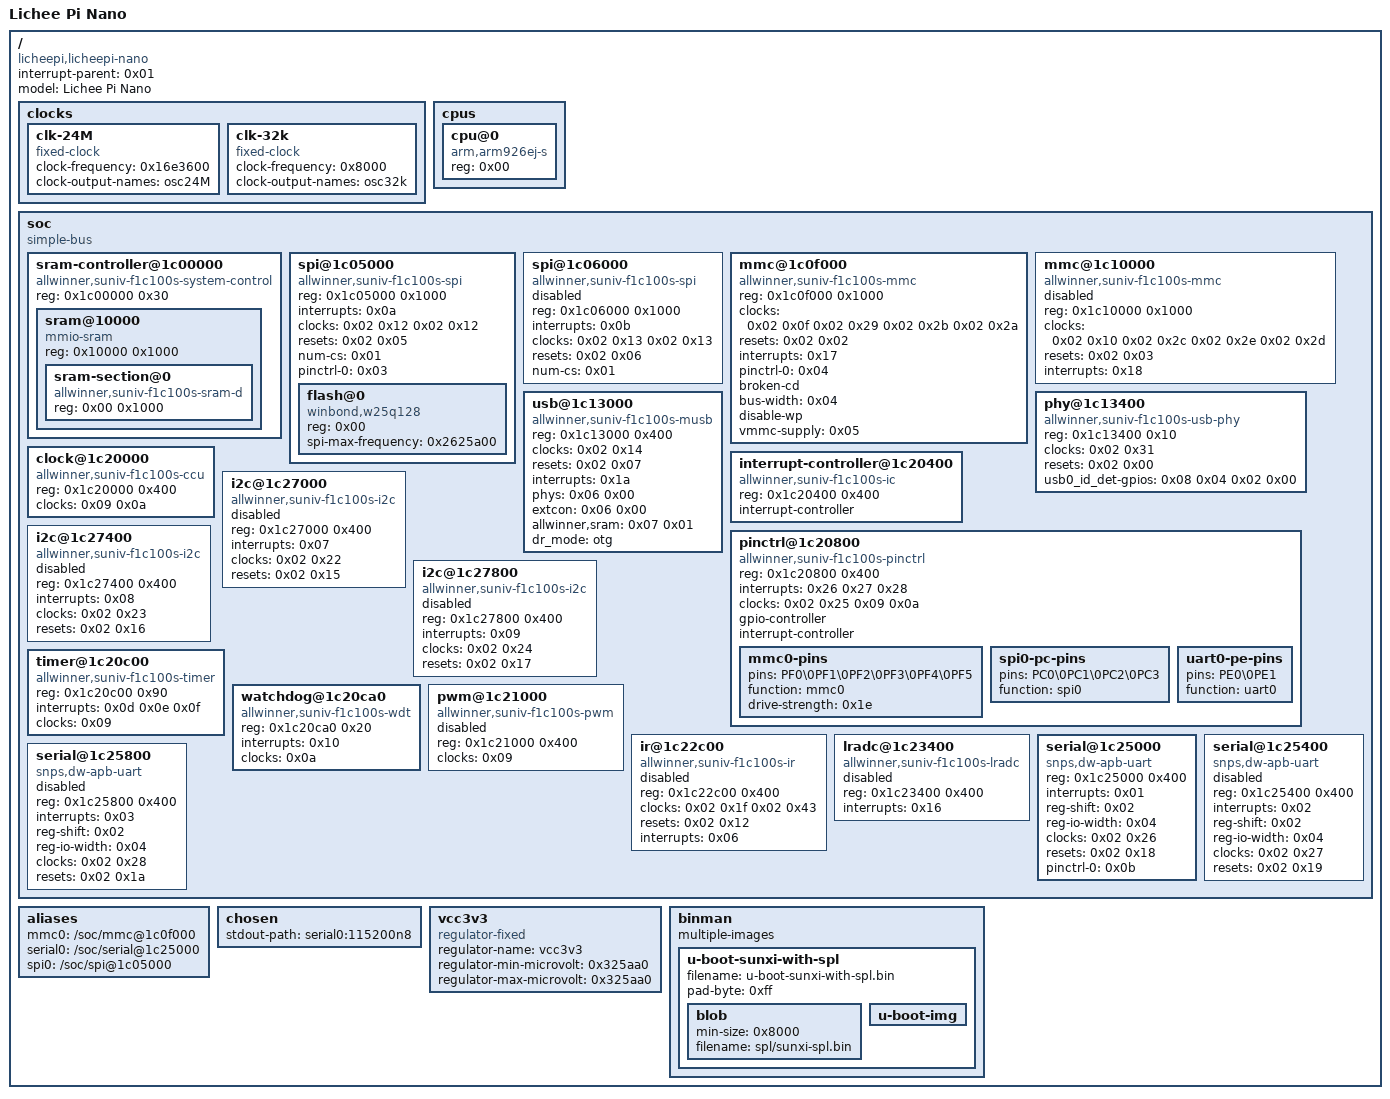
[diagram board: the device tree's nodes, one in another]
/dts-v1/;

/ {
	#address-cells = <0x01>;
	#size-cells = <0x01>;
	interrupt-parent = <0x01>;
	model = "Lichee Pi Nano";
	compatible = "licheepi,licheepi-nano\0allwinner,suniv-f1c100s";

	clocks {

		clk-24M {
			#clock-cells = <0x00>;
			compatible = "fixed-clock";
			clock-frequency = <0x16e3600>;
			clock-output-names = "osc24M";
			phandle = <0x09>;
		};

		clk-32k {
			#clock-cells = <0x00>;
			compatible = "fixed-clock";
			clock-frequency = <0x8000>;
			clock-output-names = "osc32k";
			phandle = <0x0a>;
		};
	};

	cpus {
		#address-cells = <0x01>;
		#size-cells = <0x00>;

		cpu@0 {
			compatible = "arm,arm926ej-s";
			device_type = "cpu";
			reg = <0x00>;
		};
	};

	soc {
		compatible = "simple-bus";
		#address-cells = <0x01>;
		#size-cells = <0x01>;
		ranges;

		sram-controller@1c00000 {
			compatible = "allwinner,suniv-f1c100s-system-control\0allwinner,sun4i-a10-system-control";
			reg = <0x1c00000 0x30>;
			#address-cells = <0x01>;
			#size-cells = <0x01>;
			ranges;

			sram@10000 {
				compatible = "mmio-sram";
				reg = <0x10000 0x1000>;
				#address-cells = <0x01>;
				#size-cells = <0x01>;
				ranges = <0x00 0x10000 0x1000>;
				phandle = <0x0c>;

				sram-section@0 {
					compatible = "allwinner,suniv-f1c100s-sram-d\0allwinner,sun4i-a10-sram-d";
					reg = <0x00 0x1000>;
					status = "okay";
					phandle = <0x07>;
				};
			};
		};

		spi@1c05000 {
			compatible = "allwinner,suniv-f1c100s-spi\0allwinner,sun8i-h3-spi";
			reg = <0x1c05000 0x1000>;
			interrupts = <0x0a>;
			clocks = <0x02 0x12 0x02 0x12>;
			clock-names = "ahb\0mod";
			resets = <0x02 0x05>;
			status = "okay";
			num-cs = <0x01>;
			#address-cells = <0x01>;
			#size-cells = <0x00>;
			pinctrl-names = "default";
			pinctrl-0 = <0x03>;
			phandle = <0x0d>;

			flash@0 {
				#address-cells = <0x01>;
				#size-cells = <0x01>;
				compatible = "winbond,w25q128\0jedec,spi-nor";
				reg = <0x00>;
				spi-max-frequency = <0x2625a00>;
			};
		};

		spi@1c06000 {
			compatible = "allwinner,suniv-f1c100s-spi\0allwinner,sun8i-h3-spi";
			reg = <0x1c06000 0x1000>;
			interrupts = <0x0b>;
			clocks = <0x02 0x13 0x02 0x13>;
			clock-names = "ahb\0mod";
			resets = <0x02 0x06>;
			status = "disabled";
			num-cs = <0x01>;
			#address-cells = <0x01>;
			#size-cells = <0x00>;
			phandle = <0x0e>;
		};

		mmc@1c0f000 {
			compatible = "allwinner,suniv-f1c100s-mmc\0allwinner,sun7i-a20-mmc";
			reg = <0x1c0f000 0x1000>;
			clocks = <0x02 0x0f 0x02 0x29 0x02 0x2b 0x02 0x2a>;
			clock-names = "ahb\0mmc\0output\0sample";
			resets = <0x02 0x02>;
			reset-names = "ahb";
			interrupts = <0x17>;
			pinctrl-names = "default";
			pinctrl-0 = <0x04>;
			status = "okay";
			#address-cells = <0x01>;
			#size-cells = <0x00>;
			broken-cd;
			bus-width = <0x04>;
			disable-wp;
			vmmc-supply = <0x05>;
			phandle = <0x0f>;
		};

		mmc@1c10000 {
			compatible = "allwinner,suniv-f1c100s-mmc\0allwinner,sun7i-a20-mmc";
			reg = <0x1c10000 0x1000>;
			clocks = <0x02 0x10 0x02 0x2c 0x02 0x2e 0x02 0x2d>;
			clock-names = "ahb\0mmc\0output\0sample";
			resets = <0x02 0x03>;
			reset-names = "ahb";
			interrupts = <0x18>;
			status = "disabled";
			#address-cells = <0x01>;
			#size-cells = <0x00>;
			phandle = <0x10>;
		};

		usb@1c13000 {
			compatible = "allwinner,suniv-f1c100s-musb";
			reg = <0x1c13000 0x400>;
			clocks = <0x02 0x14>;
			resets = <0x02 0x07>;
			interrupts = <0x1a>;
			interrupt-names = "mc";
			phys = <0x06 0x00>;
			phy-names = "usb";
			extcon = <0x06 0x00>;
			allwinner,sram = <0x07 0x01>;
			status = "okay";
			dr_mode = "otg";
			phandle = <0x11>;
		};

		phy@1c13400 {
			compatible = "allwinner,suniv-f1c100s-usb-phy";
			reg = <0x1c13400 0x10>;
			reg-names = "phy_ctrl";
			clocks = <0x02 0x31>;
			clock-names = "usb0_phy";
			resets = <0x02 0x00>;
			reset-names = "usb0_reset";
			#phy-cells = <0x01>;
			status = "okay";
			usb0_id_det-gpios = <0x08 0x04 0x02 0x00>;
			phandle = <0x06>;
		};

		clock@1c20000 {
			compatible = "allwinner,suniv-f1c100s-ccu";
			reg = <0x1c20000 0x400>;
			clocks = <0x09 0x0a>;
			clock-names = "hosc\0losc";
			#clock-cells = <0x01>;
			#reset-cells = <0x01>;
			phandle = <0x02>;
		};

		interrupt-controller@1c20400 {
			compatible = "allwinner,suniv-f1c100s-ic";
			reg = <0x1c20400 0x400>;
			interrupt-controller;
			#interrupt-cells = <0x01>;
			phandle = <0x01>;
		};

		pinctrl@1c20800 {
			compatible = "allwinner,suniv-f1c100s-pinctrl";
			reg = <0x1c20800 0x400>;
			interrupts = <0x26 0x27 0x28>;
			clocks = <0x02 0x25 0x09 0x0a>;
			clock-names = "apb\0hosc\0losc";
			gpio-controller;
			interrupt-controller;
			#interrupt-cells = <0x03>;
			#gpio-cells = <0x03>;
			phandle = <0x08>;

			mmc0-pins {
				pins = "PF0\0PF1\0PF2\0PF3\0PF4\0PF5";
				function = "mmc0";
				drive-strength = <0x1e>;
				phandle = <0x04>;
			};

			spi0-pc-pins {
				pins = "PC0\0PC1\0PC2\0PC3";
				function = "spi0";
				phandle = <0x03>;
			};

			uart0-pe-pins {
				pins = "PE0\0PE1";
				function = "uart0";
				phandle = <0x0b>;
			};
		};

		i2c@1c27000 {
			compatible = "allwinner,suniv-f1c100s-i2c\0allwinner,sun6i-a31-i2c";
			reg = <0x1c27000 0x400>;
			interrupts = <0x07>;
			clocks = <0x02 0x22>;
			resets = <0x02 0x15>;
			#address-cells = <0x01>;
			#size-cells = <0x00>;
			status = "disabled";
			phandle = <0x12>;
		};

		i2c@1c27400 {
			compatible = "allwinner,suniv-f1c100s-i2c\0allwinner,sun6i-a31-i2c";
			reg = <0x1c27400 0x400>;
			interrupts = <0x08>;
			clocks = <0x02 0x23>;
			resets = <0x02 0x16>;
			#address-cells = <0x01>;
			#size-cells = <0x00>;
			status = "disabled";
			phandle = <0x13>;
		};

		i2c@1c27800 {
			compatible = "allwinner,suniv-f1c100s-i2c\0allwinner,sun6i-a31-i2c";
			reg = <0x1c27800 0x400>;
			interrupts = <0x09>;
			clocks = <0x02 0x24>;
			resets = <0x02 0x17>;
			#address-cells = <0x01>;
			#size-cells = <0x00>;
			status = "disabled";
			phandle = <0x14>;
		};

		timer@1c20c00 {
			compatible = "allwinner,suniv-f1c100s-timer";
			reg = <0x1c20c00 0x90>;
			interrupts = <0x0d 0x0e 0x0f>;
			clocks = <0x09>;
		};

		watchdog@1c20ca0 {
			compatible = "allwinner,suniv-f1c100s-wdt\0allwinner,sun6i-a31-wdt";
			reg = <0x1c20ca0 0x20>;
			interrupts = <0x10>;
			clocks = <0x0a>;
			phandle = <0x15>;
		};

		pwm@1c21000 {
			compatible = "allwinner,suniv-f1c100s-pwm\0allwinner,sun7i-a20-pwm";
			reg = <0x1c21000 0x400>;
			clocks = <0x09>;
			#pwm-cells = <0x03>;
			status = "disabled";
			phandle = <0x16>;
		};

		ir@1c22c00 {
			compatible = "allwinner,suniv-f1c100s-ir\0allwinner,sun6i-a31-ir";
			reg = <0x1c22c00 0x400>;
			clocks = <0x02 0x1f 0x02 0x43>;
			clock-names = "apb\0ir";
			resets = <0x02 0x12>;
			interrupts = <0x06>;
			status = "disabled";
			phandle = <0x17>;
		};

		lradc@1c23400 {
			compatible = "allwinner,suniv-f1c100s-lradc\0allwinner,sun8i-a83t-r-lradc";
			reg = <0x1c23400 0x400>;
			interrupts = <0x16>;
			status = "disabled";
			phandle = <0x18>;
		};

		serial@1c25000 {
			compatible = "snps,dw-apb-uart";
			reg = <0x1c25000 0x400>;
			interrupts = <0x01>;
			reg-shift = <0x02>;
			reg-io-width = <0x04>;
			clocks = <0x02 0x26>;
			resets = <0x02 0x18>;
			status = "okay";
			pinctrl-names = "default";
			pinctrl-0 = <0x0b>;
			phandle = <0x19>;
		};

		serial@1c25400 {
			compatible = "snps,dw-apb-uart";
			reg = <0x1c25400 0x400>;
			interrupts = <0x02>;
			reg-shift = <0x02>;
			reg-io-width = <0x04>;
			clocks = <0x02 0x27>;
			resets = <0x02 0x19>;
			status = "disabled";
			phandle = <0x1a>;
		};

		serial@1c25800 {
			compatible = "snps,dw-apb-uart";
			reg = <0x1c25800 0x400>;
			interrupts = <0x03>;
			reg-shift = <0x02>;
			reg-io-width = <0x04>;
			clocks = <0x02 0x28>;
			resets = <0x02 0x1a>;
			status = "disabled";
			phandle = <0x1b>;
		};
	};

	aliases {
		mmc0 = "/soc/mmc@1c0f000";
		serial0 = "/soc/serial@1c25000";
		spi0 = "/soc/spi@1c05000";
	};

	chosen {
		stdout-path = "serial0:115200n8";
	};

	vcc3v3 {
		compatible = "regulator-fixed";
		regulator-name = "vcc3v3";
		regulator-min-microvolt = <0x325aa0>;
		regulator-max-microvolt = <0x325aa0>;
		phandle = <0x05>;
	};

	binman {
		multiple-images;
		phandle = <0x1c>;

		u-boot-sunxi-with-spl {
			filename = "u-boot-sunxi-with-spl.bin";
			pad-byte = <0xff>;

			blob {
				min-size = <0x8000>;
				filename = "spl/sunxi-spl.bin";
			};

			u-boot-img {
			};
		};
	};

	__symbols__ {
		osc24M = "/clocks/clk-24M";
		osc32k = "/clocks/clk-32k";
		sram_d = "/soc/sram-controller@1c00000/sram@10000";
		otg_sram = "/soc/sram-controller@1c00000/sram@10000/sram-section@0";
		spi0 = "/soc/spi@1c05000";
		spi1 = "/soc/spi@1c06000";
		mmc0 = "/soc/mmc@1c0f000";
		mmc1 = "/soc/mmc@1c10000";
		usb_otg = "/soc/usb@1c13000";
		usbphy = "/soc/phy@1c13400";
		ccu = "/soc/clock@1c20000";
		intc = "/soc/interrupt-controller@1c20400";
		pio = "/soc/pinctrl@1c20800";
		mmc0_pins = "/soc/pinctrl@1c20800/mmc0-pins";
		spi0_pc_pins = "/soc/pinctrl@1c20800/spi0-pc-pins";
		uart0_pe_pins = "/soc/pinctrl@1c20800/uart0-pe-pins";
		i2c0 = "/soc/i2c@1c27000";
		i2c1 = "/soc/i2c@1c27400";
		i2c2 = "/soc/i2c@1c27800";
		wdt = "/soc/watchdog@1c20ca0";
		pwm = "/soc/pwm@1c21000";
		ir = "/soc/ir@1c22c00";
		lradc = "/soc/lradc@1c23400";
		uart0 = "/soc/serial@1c25000";
		uart1 = "/soc/serial@1c25400";
		uart2 = "/soc/serial@1c25800";
		reg_vcc3v3 = "/vcc3v3";
		binman = "/binman";
	};
};
